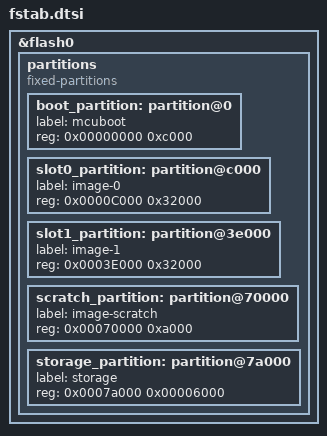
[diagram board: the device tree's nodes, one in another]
/* Flash partition table without support for Nordic nRF5 bootloader */

&flash0 {
	partitions {
		compatible = "fixed-partitions";
		#address-cells = <1>;
		#size-cells = <1>;

		boot_partition: partition@0 {
			label = "mcuboot";
			reg = <0x00000000 0xc000>;
		};
		slot0_partition: partition@c000 {
			label = "image-0";
			reg = <0x0000C000 0x32000>;
		};
		slot1_partition: partition@3e000 {
			label = "image-1";
			reg = <0x0003E000 0x32000>;
		};
		scratch_partition: partition@70000 {
			label = "image-scratch";
			reg = <0x00070000 0xa000>;
		};

		/*
		 * The flash starting at 0x0007a000 and ending at
		 * 0x0007ffff (sectors 122-127) is reserved for use
		 * by the application.
		 * Storage partition will be used by FCB/LittleFS/NVS
		 * if enabled.
		 */
		storage_partition: partition@7a000 {
			label = "storage";
			reg = <0x0007a000 0x00006000>;
		};
	};
};
